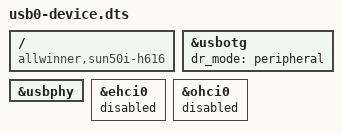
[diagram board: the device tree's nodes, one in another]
/dts-v1/;
/plugin/;
/ {
  compatible = "allwinner,sun50i-h616", "allwinner,sun50i-h618";

  fragment@0 { target = <&usbotg>; __overlay__ { dr_mode = "peripheral"; status = "okay"; }; };
  fragment@1 { target = <&usbphy>;  __overlay__ { status = "okay"; }; };
  /* Prevent host controllers from grabbing PHY0 */
  fragment@2 { target = <&ehci0>;  __overlay__ { status = "disabled"; }; };
  fragment@3 { target = <&ohci0>;  __overlay__ { status = "disabled"; }; };
};
